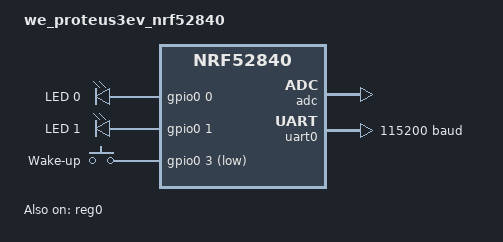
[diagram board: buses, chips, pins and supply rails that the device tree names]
/* Copyright (c) 2022 Nordic Semiconductor ASA */
/* SPDX-License-Identifier: Apache-2.0 */

/dts-v1/;
#include <nordic/nrf52840_qiaa.dtsi>
#include <nordic/nrf52840_partition.dtsi>
#include "we_proteus3ev_nrf52840-pinctrl.dtsi"
#include <zephyr/dt-bindings/input/input-event-codes.h>

/ {
	model = "we_proteus3ev_nrf52840";
	compatible = "we,we-proteus3ev-nrf52840";

	chosen {
		zephyr,console = &uart0;
		zephyr,shell-uart = &uart0;
		zephyr,uart-mcumgr = &uart0;
		zephyr,bt-mon-uart = &uart0;
		zephyr,bt-c2h-uart = &uart0;
	};

	leds {
		compatible = "gpio-leds";
		led0: led_0 {
			gpios = <&gpio0 0 GPIO_ACTIVE_HIGH>;
			label = "LED 0";
		};
		led1: led_1 {
			gpios = <&gpio0 1 GPIO_ACTIVE_HIGH>;
			label = "LED 1";
		};
	};

	buttons {
		compatible = "gpio-keys";
		button0: button_0 {
			gpios = <&gpio0 3 (GPIO_PULL_UP | GPIO_ACTIVE_LOW)>;
			label = "Wake-up";
			zephyr,code = <INPUT_KEY_0>;
		};
	};


	/* These aliases are provided for compatibility with samples */
	aliases {
		led0 = &led0;
		led1 = &led1;
		sw0 = &button0;
		bootloader-led0 = &led0;
		watchdog0 = &wdt0;
	};
};

&reg0 {
	status = "okay";
};

&reg1 {
	regulator-initial-mode = <NRF5X_REG_MODE_DCDC>;
};

&adc {
	status = "okay";
};

&uicr {
	gpio-as-nreset;
};

&gpiote {
	status = "okay";
};

&gpio0 {
	status = "okay";
};

&gpio1 {
	status = "okay";
};

&uart0 {
	compatible = "nordic,nrf-uarte";
	status = "okay";
	current-speed = <115200>;
	pinctrl-0 = <&uart0_default>;
	pinctrl-1 = <&uart0_sleep>;
	pinctrl-names = "default", "sleep";
};

&i2c0 {
	compatible = "nordic,nrf-twi";
	/* Cannot be used together with spi1. */
	/* status = "okay"; */
	pinctrl-0 = <&i2c0_default>;
	pinctrl-1 = <&i2c0_sleep>;
	pinctrl-names = "default", "sleep";
};

&spi0 {
	compatible = "nordic,nrf-spi";
	/* Cannot be used together with i2c0. */
	/* status = "okay"; */
	pinctrl-0 = <&spi0_default>;
	pinctrl-1 = <&spi0_sleep>;
	pinctrl-names = "default", "sleep";
};
